# iom480ae register map
Registers are 32-bit, access not given, no defined reset value unless marked. A register's access mark holds for its fields unless they carry their own. Addresses are absolute; registers are grouped by the start of their names; [hi:lo] are bit positions; {n}, {i} and the like mark numbered series.

## CRYPTO
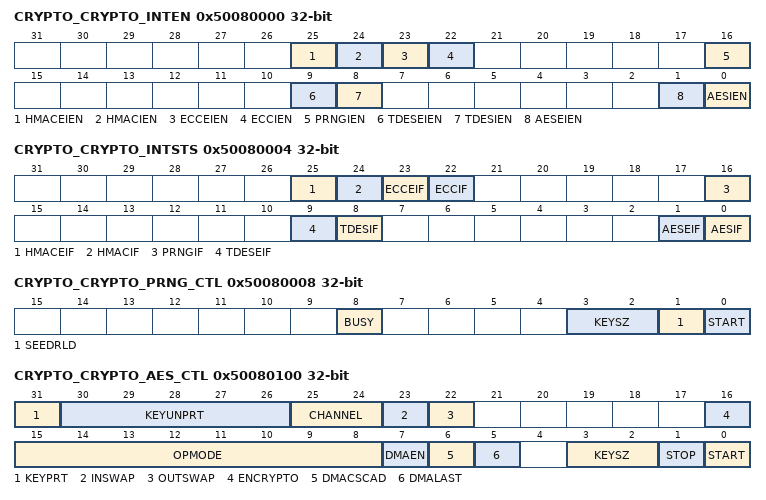
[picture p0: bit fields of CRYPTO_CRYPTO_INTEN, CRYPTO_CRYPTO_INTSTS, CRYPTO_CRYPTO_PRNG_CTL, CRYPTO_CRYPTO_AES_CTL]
0x50080000 CRYPTO_CRYPTO_INTEN
  [25] HMACEIEN, [24] HMACIEN, [23] ECCEIEN, [22] ECCIEN, [16] PRNGIEN, [9] TDESEIEN, [8] TDESIEN, [1] AESEIEN, [0] AESIEN
0x50080004 CRYPTO_CRYPTO_INTSTS
  [25] HMACEIF, [24] HMACIF, [23] ECCEIF, [22] ECCIF, [16] PRNGIF, [9] TDESEIF, [8] TDESIF, [1] AESEIF, [0] AESIF
0x50080008 CRYPTO_CRYPTO_PRNG_CTL
  [8] BUSY, [3:2] KEYSZ, [1] SEEDRLD, [0] START
0x5008000C CRYPTO_CRYPTO_PRNG_SEED
{0x50080010+4i} CRYPTO_CRYPTO_PRNG_KEY{i} (i=0..7)
{0x50080050+4i} CRYPTO_CRYPTO_AES_FDBCK{i} (i=0..3)
0x50080060 CRYPTO_CRYPTO_TDES_FDBCKH
0x50080064 CRYPTO_CRYPTO_TDES_FDBCKL
0x50080100 CRYPTO_CRYPTO_AES_CTL
  [31] KEYPRT, [30:26] KEYUNPRT, [25:24] CHANNEL, [23] INSWAP, [22] OUTSWAP, [16] ENCRYPTO, [15:8] OPMODE, [7] DMAEN, [6] DMACSCAD, [5] DMALAST, [3:2] KEYSZ, [1] STOP, [0] START
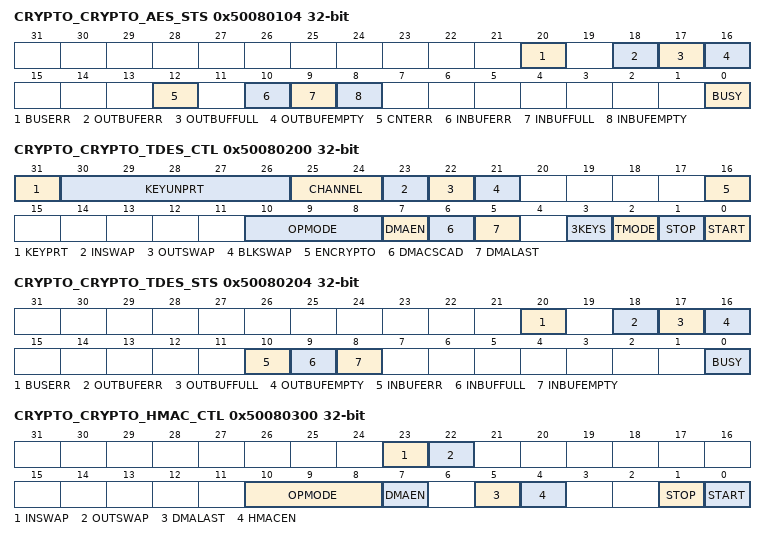
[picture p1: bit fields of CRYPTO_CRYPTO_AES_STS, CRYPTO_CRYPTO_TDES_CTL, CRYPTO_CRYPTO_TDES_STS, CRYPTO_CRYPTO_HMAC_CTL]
0x50080104 CRYPTO_CRYPTO_AES_STS
  [20] BUSERR, [18] OUTBUFERR, [17] OUTBUFFULL, [16] OUTBUFEMPTY, [12] CNTERR, [10] INBUFERR, [9] INBUFFULL, [8] INBUFEMPTY, [0] BUSY
0x50080108 CRYPTO_CRYPTO_AES_DATIN
0x5008010C CRYPTO_CRYPTO_AES_DATOUT
{0x50080110+4i} CRYPTO_CRYPTO_AES0_KEY{i} (i=0..7)
{0x50080130+0x3C*i} CRYPTO_CRYPTO_AES{i}_IV0 (i=0..3)
{0x50080134+0x3C*i} CRYPTO_CRYPTO_AES{i}_IV1 (i=0..3)
{0x50080138+0x3C*i} CRYPTO_CRYPTO_AES{i}_IV2 (i=0..3)
{0x5008013C+0x3C*i} CRYPTO_CRYPTO_AES{i}_IV3 (i=0..3)
{0x50080140+0x3C*i} CRYPTO_CRYPTO_AES{i}_SADDR (i=0..3)
{0x50080144+0x3C*i} CRYPTO_CRYPTO_AES{i}_DADDR (i=0..3)
{0x50080148+0x3C*i} CRYPTO_CRYPTO_AES{i}_CNT (i=0..3)
{0x5008014C+4i} CRYPTO_CRYPTO_AES1_KEY{i} (i=0..7)
{0x50080188+4i} CRYPTO_CRYPTO_AES2_KEY{i} (i=0..7)
{0x500801C4+4i} CRYPTO_CRYPTO_AES3_KEY{i} (i=0..7)
0x50080200 CRYPTO_CRYPTO_TDES_CTL
  [31] KEYPRT, [30:26] KEYUNPRT, [25:24] CHANNEL, [23] INSWAP, [22] OUTSWAP, [21] BLKSWAP, [16] ENCRYPTO, [10:8] OPMODE, [7] DMAEN, [6] DMACSCAD, [5] DMALAST, [3] 3KEYS, [2] TMODE, [1] STOP, [0] START
0x50080204 CRYPTO_CRYPTO_TDES_STS
  [20] BUSERR, [18] OUTBUFERR, [17] OUTBUFFULL, [16] OUTBUFEMPTY, [10] INBUFERR, [9] INBUFFULL, [8] INBUFEMPTY, [0] BUSY
{0x50080208+0x40*i} CRYPTO_CRYPTO_TDES{i}_KEY1H (i=0..3)
{0x5008020C+0x40*i} CRYPTO_CRYPTO_TDES{i}_KEY1L (i=0..3)
{0x50080210+0x40*i} CRYPTO_CRYPTO_TDES{i}_KEY2H (i=0..3)
{0x50080214+0x40*i} CRYPTO_CRYPTO_TDES{i}_KEY2L (i=0..3)
{0x50080218+0x40*i} CRYPTO_CRYPTO_TDES{i}_KEY3H (i=0..3)
{0x5008021C+0x40*i} CRYPTO_CRYPTO_TDES{i}_KEY3L (i=0..3)
{0x50080220+0x40*i} CRYPTO_CRYPTO_TDES{i}_IVH (i=0..3)
{0x50080224+0x40*i} CRYPTO_CRYPTO_TDES{i}_IVL (i=0..3)
{0x50080228+0x40*i} CRYPTO_CRYPTO_TDES{i}_SADDR (i=0..3)
{0x5008022C+0x40*i} CRYPTO_CRYPTO_TDES{i}_DADDR (i=0..3)
{0x50080230+0x40*i} CRYPTO_CRYPTO_TDES{i}_CNT (i=0..3)
0x50080234 CRYPTO_CRYPTO_TDES_DATIN
0x50080238 CRYPTO_CRYPTO_TDES_DATOUT
0x50080300 CRYPTO_CRYPTO_HMAC_CTL
  [23] INSWAP, [22] OUTSWAP, [10:8] OPMODE, [7] DMAEN, [5] DMALAST, [4] HMACEN, [1] STOP, [0] START
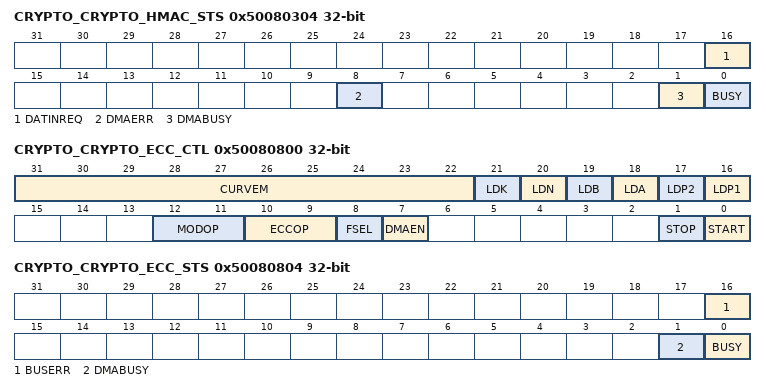
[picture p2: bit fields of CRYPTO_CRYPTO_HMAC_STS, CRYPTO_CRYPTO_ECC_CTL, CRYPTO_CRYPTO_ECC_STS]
0x50080304 CRYPTO_CRYPTO_HMAC_STS
  [16] DATINREQ, [8] DMAERR, [1] DMABUSY, [0] BUSY
{0x50080308+4i} CRYPTO_CRYPTO_HMAC_DGST{i} (i=0..15)
0x50080348 CRYPTO_CRYPTO_HMAC_KEYCNT
0x5008034C CRYPTO_CRYPTO_HMAC_SADDR
0x50080350 CRYPTO_CRYPTO_HMAC_DMACNT
0x50080354 CRYPTO_CRYPTO_HMAC_DATIN
0x50080800 CRYPTO_CRYPTO_ECC_CTL
  [31:22] CURVEM, [21] LDK, [20] LDN, [19] LDB, [18] LDA, [17] LDP2, [16] LDP1, [12:11] MODOP, [10:9] ECCOP, [8] FSEL, [7] DMAEN, [1] STOP, [0] START
0x50080804 CRYPTO_CRYPTO_ECC_STS
  [16] BUSERR, [1] DMABUSY, [0] BUSY
{0x50080808+4i} CRYPTO_CRYPTO_ECC_X1_{i:02} (i=0..17)
{0x50080850+4i} CRYPTO_CRYPTO_ECC_Y1_{i:02} (i=0..17)
{0x50080898+4i} CRYPTO_CRYPTO_ECC_X2_{i:02} (i=0..17)
{0x500808E0+4i} CRYPTO_CRYPTO_ECC_Y2_{i:02} (i=0..17)
{0x50080928+4i} CRYPTO_CRYPTO_ECC_A_{i:02} (i=0..17)
{0x50080970+4i} CRYPTO_CRYPTO_ECC_B_{i:02} (i=0..17)
{0x500809B8+4i} CRYPTO_CRYPTO_ECC_N_{i:02} (i=0..17)
{0x50080A00+4i} CRYPTO_CRYPTO_ECC_K_{i:02} (i=0..17)
0x50080A48 CRYPTO_CRYPTO_ECC_SADDR
0x50080A4C CRYPTO_CRYPTO_ECC_DADDR
0x50080A50 CRYPTO_CRYPTO_ECC_STARTREG
0x50080A54 CRYPTO_CRYPTO_ECC_WORDCNT
